# N32G031 register map
Vendor: Nationstech Ltd.; File version: 1.0
Registers are 32-bit, read-write, reset 0x0 unless marked. A register's access mark holds for its fields unless they carry their own. Offsets are from the block's base; [hi:lo] are bit positions; {n}, {i} and the like mark numbered series; 'fields as' and 'values as' point back to an identical list.

## BEEPER — Beeper unit
Base 0x40000000
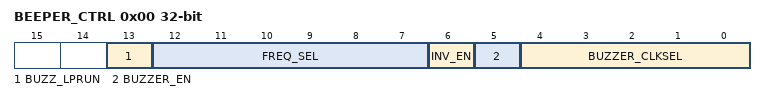
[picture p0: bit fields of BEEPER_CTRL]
0x00 BEEPER_CTRL
  [13] BUZZ_LPRUN, [12:7] FREQ_SEL, [6] INV_EN, [5] BUZZER_EN, [4:0] BUZZER_CLKSEL

## COMP — comparator
Base 0x40002400
0x00 COMP_INTEN
  [0] CMPIEN
0x04 COMP_INTSTS
  [0] CMPIS
0x0C COMP_LOCK
  [0] CMPLK
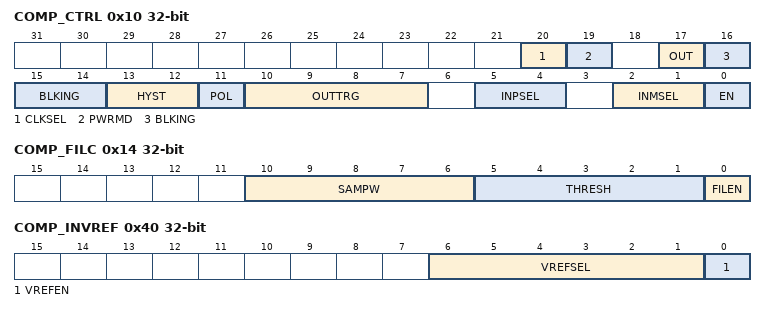
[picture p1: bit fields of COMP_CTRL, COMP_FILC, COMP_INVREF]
0x10 COMP_CTRL
  [20] CLKSEL
  [19] PWRMD
  [17] OUT
  [16:14] BLKING
  [13:12] HYST
  [11] POL
  [10:7] OUTTRG — OUTSEL
  [5:4] INPSEL
  [2:1] INMSEL
  [0] EN
0x14 COMP_FILC
  [10:6] SAMPW, [5:1] THRESH, [0] FILEN
0x18 COMP_FILP
  [15:0] CLKPSC
0x40 COMP_INVREF
  [6:1] VREFSEL, [0] VREFEN

## CRC — cyclic redundancy check
Base 0x40023000
0x00 CRC32DAT reset 0xFFFFFFFF
0x04 CRC32IDAT
  [7:0] CRC32IDAT
0x08 CRC32CTRL
  [0] RESET
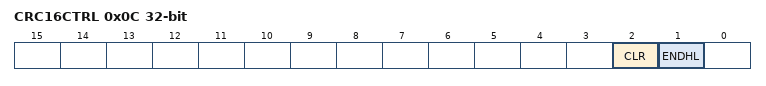
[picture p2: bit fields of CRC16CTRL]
0x0C CRC16CTRL
  [2] CLR, [1] ENDHL
0x10 CRC16DAT
  [7:0] CRC16DAT
0x14 CRC16D
  [15:0] CRC16D
0x18 LRC
  [7:0] LRCDAT

## DMA — Direct memory access controller
Base 0x40020000
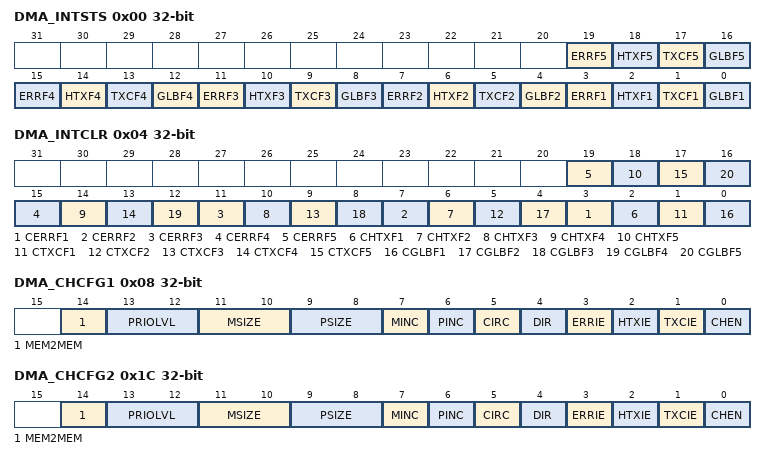
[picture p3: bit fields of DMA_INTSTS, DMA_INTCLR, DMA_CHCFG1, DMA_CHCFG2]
0x00 DMA_INTSTS
  [4n-1] ERRF{n} (n=1..5), [4n-2] HTXF{n} (n=1..5), [4n-3] TXCF{n} (n=1..5), [4n-4] GLBF{n} (n=1..5)
0x04 DMA_INTCLR
  [4n-1] CERRF{n} (n=1..5), [4n-2] CHTXF{n} (n=1..5), [4n-3] CTXCF{n} (n=1..5), [4n-4] CGLBF{n} (n=1..5)
0x08 DMA_CHCFG1
  [14] MEM2MEM, [13:12] PRIOLVL, [11:10] MSIZE, [9:8] PSIZE, [7] MINC, [6] PINC, [5] CIRC, [4] DIR, [3] ERRIE, [2] HTXIE, [1] TXCIE, [0] CHEN
0x0C DMA_TXNUM1
  [15:0] NDTX
0x10 DMA_PADDR1
  [31:0] ADDR
{0x0+0x14*i} DMA_MADDR{i} (i=1..5)
  [31:0] ADDR
{0x4+0x14*i} DMA_CHSEL{i} (i=1..5)
  [5:0] CH_SEL
0x1C DMA_CHCFG2
  fields as DMA_CHCFG1
0x20 DMA_TXNUM2
  [15:0] NDTX
0x24 DMA_PADDR2
  [31:0] ADDR
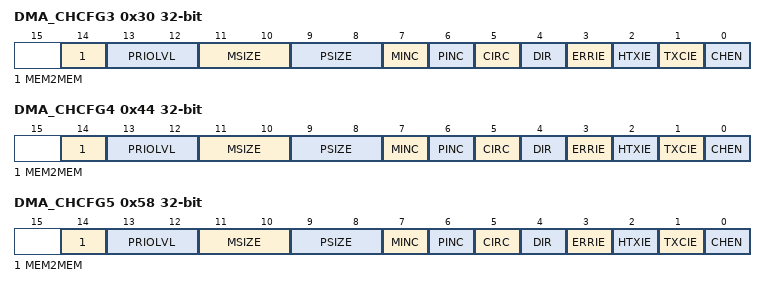
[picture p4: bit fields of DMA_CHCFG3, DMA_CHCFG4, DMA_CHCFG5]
0x30 DMA_CHCFG3
  fields as DMA_CHCFG1
0x34 DMA_TXNUM3
  [15:0] NDTX
0x38 DMA_PADDR3
  [31:0] ADDR
0x44 DMA_CHCFG4
  fields as DMA_CHCFG1
0x48 DMA_TXNUM4
  [15:0] NDTX
0x4C DMA_PADDR4
  [31:0] ADDR
0x58 DMA_CHCFG5
  fields as DMA_CHCFG1
0x5C DMA_TXNUM5
  [15:0] NDTX
0x60 DMA_PADDR5
  [31:0] ADDR

## EXTI — external interrupt/event controller
Base 0x40010400
0x00 EXTI_IMASK (reset mask 0xDFFFFF)
  [23:0] IMASK
0x04 EXTI_EMASK (reset mask 0xDFFFFF)
  [23:0] EMASK
0x08 EXTI_RT_CFG (reset mask 0xDFFFFF)
  [23:0] RT_CFG
0x0C EXTI_FT_CFG (reset mask 0xDFFFFF)
  [23:0] FT_CFG
0x10 EXTI_SWIE (reset mask 0xDFFFFF)
  [23:0] SWIE
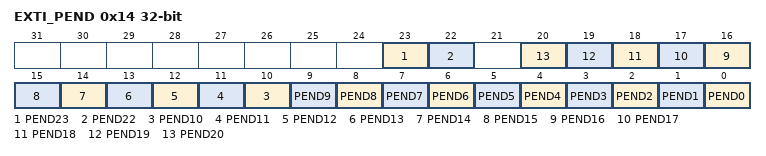
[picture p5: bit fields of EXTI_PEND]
0x14 EXTI_PEND
  [23] PEND23, [22] PEND22, [n] PEND{n} (n=0..20)
0x18 EXTI_TS_SEL
  [3:0] TSSEL

## FLASH — interal FLASH controller
Base 0x40022000
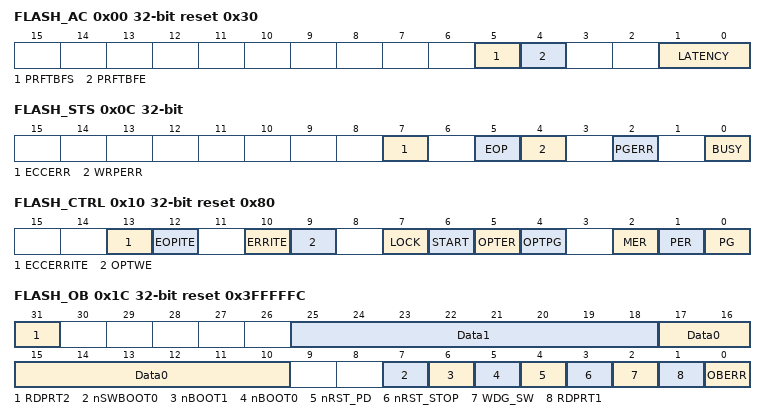
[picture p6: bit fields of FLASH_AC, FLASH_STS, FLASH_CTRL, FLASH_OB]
0x00 FLASH_AC reset 0x30
  [5] PRFTBFS, [4] PRFTBFE, [1:0] LATENCY
0x04 FLASH_KEY
  [31:0] FKEY
0x08 FLASH_OPTKEY
0x0C FLASH_STS
  [7] ECCERR, [5] EOP, [4] WRPERR, [2] PGERR, [0] BUSY
0x10 FLASH_CTRL reset 0x80
  [13] ECCERRITE, [12] EOPITE, [10] ERRITE, [9] OPTWE, [7] LOCK, [6] START, [5] OPTER, [4] OPTPG, [2] MER, [1] PER, [0] PG
0x14 FLASH_ADD
  [31:0] FADD
0x1C FLASH_OB reset 0x3FFFFFC
  [31] RDPRT2, [25:18] Data1, [17:10] Data0, [7] nSWBOOT0, [6] nBOOT1, [5] nBOOT0, [4] nRST_PD, [3] nRST_STOP, [2] WDG_SW, [1] RDPRT1, [0] OBERR
0x20 FLASH_WRP reset 0xFFFF (reset mask 0xFFFF)
  [31:0] WRPT
0x24 FLASH_ECC
  [5:0] ECC

## GPIOA — General purpose I/O
Base 0x40010800
Same registers: GPIOB 0x40010C00, GPIOC 0x40011000, GPIOF 0x40011C00
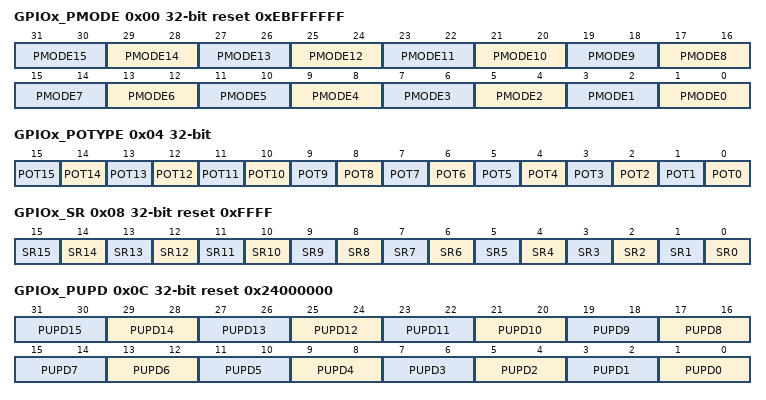
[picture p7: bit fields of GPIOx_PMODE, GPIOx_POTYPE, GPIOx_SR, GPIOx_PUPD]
0x00 GPIOx_PMODE reset 0xEBFFFFFF
  [2n+1:2n] PMODE{n} (n=0..15)
0x04 GPIOx_POTYPE
  [n] POT{n} (n=0..15)
0x08 GPIOx_SR reset 0xFFFF
  [n] SR{n} (n=0..15)
0x0C GPIOx_PUPD reset 0x24000000
  [2n+1:2n] PUPD{n} (n=0..15)
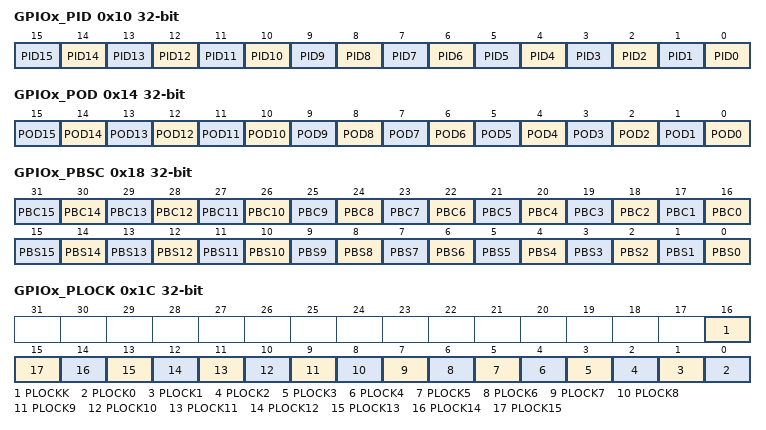
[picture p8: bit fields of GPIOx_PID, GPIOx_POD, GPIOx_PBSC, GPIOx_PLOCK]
0x10 GPIOx_PID
  [n] PID{n} (n=0..15)
0x14 GPIOx_POD
  [n] POD{n} (n=0..15)
0x18 GPIOx_PBSC
  [n+16] PBC{n} (n=0..15), [n] PBS{n} (n=0..15)
0x1C GPIOx_PLOCK
  [16] PLOCKK, [n] PLOCK{n} (n=0..15)
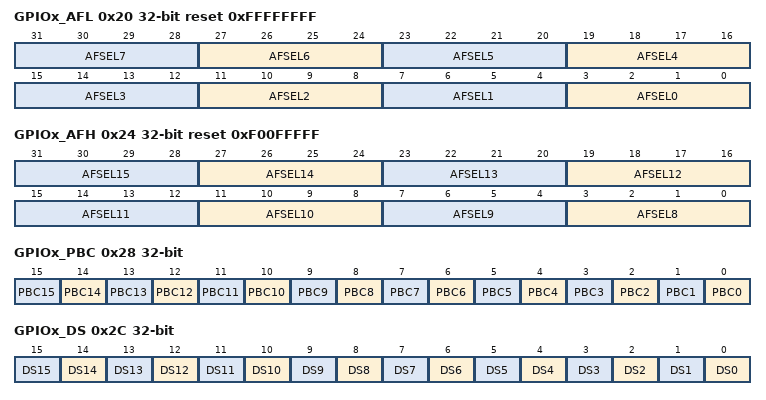
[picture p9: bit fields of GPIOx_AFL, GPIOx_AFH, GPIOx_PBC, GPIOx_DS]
0x20 GPIOx_AFL reset 0xFFFFFFFF
  [4n+3:4n] AFSEL{n} (n=0..7)
0x24 GPIOx_AFH reset 0xF00FFFFF
  [4n-29:4n-32] AFSEL{n} (n=8..15)
0x28 GPIOx_PBC
  [n] PBC{n} (n=0..15)
0x2C GPIOx_DS
  [n] DS{n} (n=0..15)
